AUTOSAR XML (schema 00046)
package /ComponentTypes
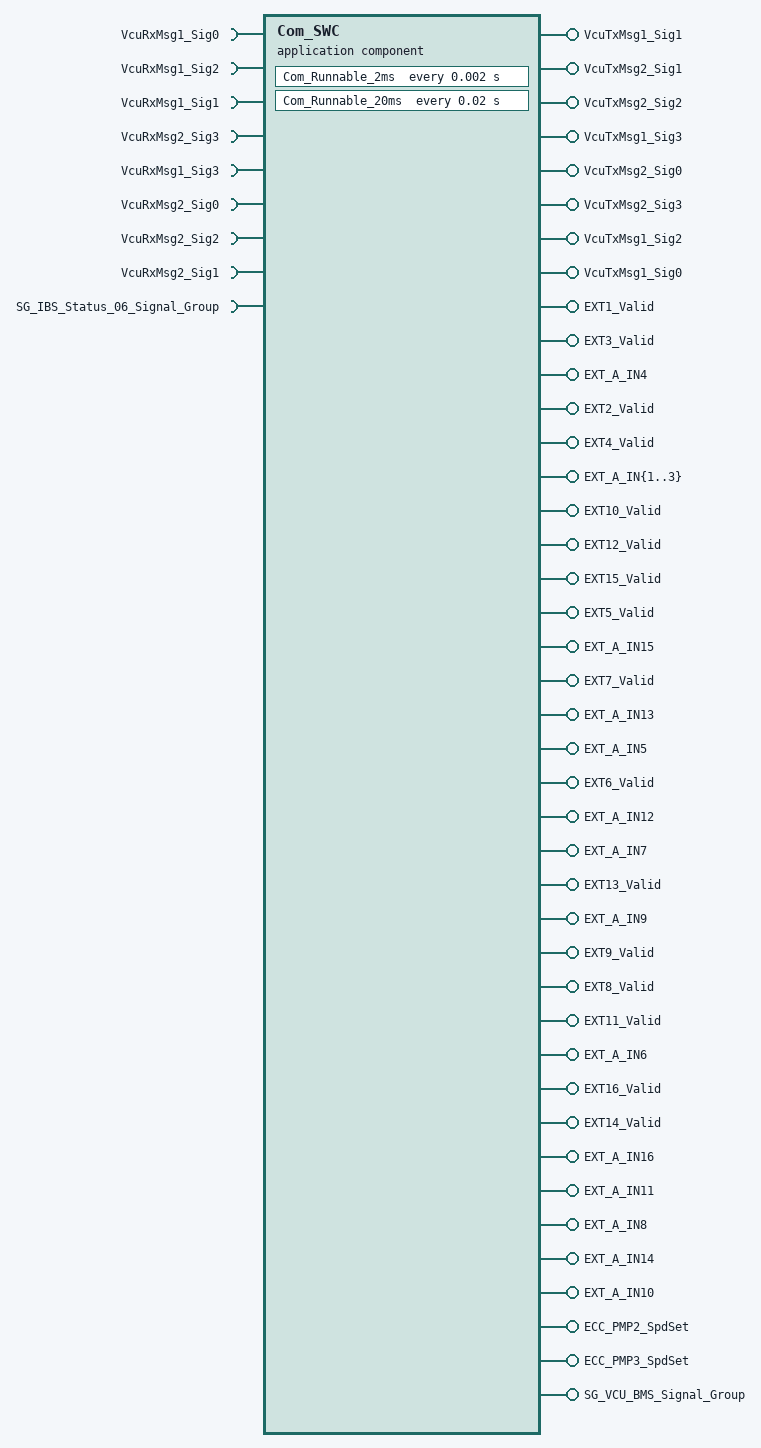
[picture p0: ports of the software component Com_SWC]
  application sw component type Com_SWC
    8 x require port:
      VcuRxMsg1_Sig0: nonqueued-receiver-com-spec{data-element=VcuRxMsg1_Sig0, alive-timeout=2, init-value=0}, required-interface=VcuRxMsg1_Sig0
      VcuRxMsg1_Sig2: nonqueued-receiver-com-spec{data-element=VcuRxMsg1_Sig2, alive-timeout=2, init-value=0}, required-interface=VcuRxMsg1_Sig2
      VcuRxMsg1_Sig1: nonqueued-receiver-com-spec{data-element=VcuRxMsg1_Sig1, alive-timeout=2, init-value=0}, required-interface=VcuRxMsg1_Sig1
      VcuRxMsg2_Sig3: nonqueued-receiver-com-spec{data-element=VcuRxMsg2_Sig3, alive-timeout=2, init-value=0}, required-interface=VcuRxMsg2_Sig3
      VcuRxMsg1_Sig3: nonqueued-receiver-com-spec{data-element=VcuRxMsg1_Sig3, alive-timeout=2, init-value=0}, required-interface=VcuRxMsg1_Sig3
      VcuRxMsg2_Sig0: nonqueued-receiver-com-spec{data-element=VcuRxMsg2_Sig0, alive-timeout=2, init-value=0}, required-interface=VcuRxMsg2_Sig0
      VcuRxMsg2_Sig2: nonqueued-receiver-com-spec{data-element=VcuRxMsg2_Sig2, alive-timeout=2, init-value=0}, required-interface=VcuRxMsg2_Sig2
      VcuRxMsg2_Sig1: nonqueued-receiver-com-spec{data-element=VcuRxMsg2_Sig1, alive-timeout=2, init-value=0}, required-interface=VcuRxMsg2_Sig1
    42 x provide port:
      VcuTxMsg1_Sig1: nonqueued-sender-com-spec{data-element=VcuTxMsg1_Sig1, init-value=0}, provided-interface=VcuTxMsg1_Sig1
      VcuTxMsg2_Sig1: nonqueued-sender-com-spec{data-element=VcuTxMsg2_Sig1, init-value=0}, provided-interface=VcuTxMsg2_Sig1
      VcuTxMsg2_Sig2: nonqueued-sender-com-spec{data-element=VcuTxMsg2_Sig2, init-value=0}, provided-interface=VcuTxMsg2_Sig2
      VcuTxMsg1_Sig3: nonqueued-sender-com-spec{data-element=VcuTxMsg1_Sig3, init-value=0}, provided-interface=VcuTxMsg1_Sig3
      VcuTxMsg2_Sig0: nonqueued-sender-com-spec{data-element=VcuTxMsg2_Sig0, init-value=0}, provided-interface=VcuTxMsg2_Sig0
      VcuTxMsg2_Sig3: nonqueued-sender-com-spec{data-element=VcuTxMsg2_Sig3, init-value=0}, provided-interface=VcuTxMsg2_Sig3
      VcuTxMsg1_Sig2: nonqueued-sender-com-spec{data-element=VcuTxMsg1_Sig2, init-value=0}, provided-interface=VcuTxMsg1_Sig2
      VcuTxMsg1_Sig0: nonqueued-sender-com-spec{data-element=VcuTxMsg1_Sig0, init-value=0}, provided-interface=VcuTxMsg1_Sig0
      EXT1_Valid: nonqueued-sender-com-spec{data-element=EXT1_Valid, init-value=0}, provided-interface=EXT1_Valid
      EXT3_Valid: nonqueued-sender-com-spec{data-element=EXT3_Valid, init-value=0}, provided-interface=EXT3_Valid
      EXT_A_IN4: nonqueued-sender-com-spec{data-element=EXT_A_IN4, init-value=0}, provided-interface=EXT_A_IN4
      EXT2_Valid: nonqueued-sender-com-spec{data-element=EXT2_Valid, init-value=0}, provided-interface=EXT2_Valid
      EXT4_Valid: nonqueued-sender-com-spec{data-element=EXT4_Valid, init-value=0}, provided-interface=EXT4_Valid
      EXT_A_IN{1..3}: nonqueued-sender-com-spec{data-element=EXT_A_IN{1..3}, init-value=0}, provided-interface=EXT_A_IN{1..3}
      EXT10_Valid: nonqueued-sender-com-spec{data-element=EXT10_Valid, init-value=0}, provided-interface=EXT10_Valid
      EXT12_Valid: nonqueued-sender-com-spec{data-element=EXT12_Valid, init-value=0}, provided-interface=EXT12_Valid
      EXT15_Valid: nonqueued-sender-com-spec{data-element=EXT15_Valid, init-value=0}, provided-interface=EXT15_Valid
      EXT5_Valid: nonqueued-sender-com-spec{data-element=EXT5_Valid, init-value=0}, provided-interface=EXT5_Valid
      EXT_A_IN15: nonqueued-sender-com-spec{data-element=EXT_A_IN15, init-value=0}, provided-interface=EXT_A_IN15
      EXT7_Valid: nonqueued-sender-com-spec{data-element=EXT7_Valid, init-value=0}, provided-interface=EXT7_Valid
      EXT_A_IN13: nonqueued-sender-com-spec{data-element=EXT_A_IN13, init-value=0}, provided-interface=EXT_A_IN13
      EXT_A_IN5: nonqueued-sender-com-spec{data-element=EXT_A_IN5, init-value=0}, provided-interface=EXT_A_IN5
      EXT6_Valid: nonqueued-sender-com-spec{data-element=EXT6_Valid, init-value=0}, provided-interface=EXT6_Valid
      EXT_A_IN12: nonqueued-sender-com-spec{data-element=EXT_A_IN12, init-value=0}, provided-interface=EXT_A_IN12
      EXT_A_IN7: nonqueued-sender-com-spec{data-element=EXT_A_IN7, init-value=0}, provided-interface=EXT_A_IN7
      EXT13_Valid: nonqueued-sender-com-spec{data-element=EXT13_Valid, init-value=0}, provided-interface=EXT13_Valid
      EXT_A_IN9: nonqueued-sender-com-spec{data-element=EXT_A_IN9, init-value=0}, provided-interface=EXT_A_IN9
      EXT9_Valid: nonqueued-sender-com-spec{data-element=EXT9_Valid, init-value=0}, provided-interface=EXT9_Valid
      EXT8_Valid: nonqueued-sender-com-spec{data-element=EXT8_Valid, init-value=0}, provided-interface=EXT8_Valid
      EXT11_Valid: nonqueued-sender-com-spec{data-element=EXT11_Valid, init-value=0}, provided-interface=EXT11_Valid
      EXT_A_IN6: nonqueued-sender-com-spec{data-element=EXT_A_IN6, init-value=0}, provided-interface=EXT_A_IN6
      EXT16_Valid: nonqueued-sender-com-spec{data-element=EXT16_Valid, init-value=0}, provided-interface=EXT16_Valid
      EXT14_Valid: nonqueued-sender-com-spec{data-element=EXT14_Valid, init-value=0}, provided-interface=EXT14_Valid
      EXT_A_IN16: nonqueued-sender-com-spec{data-element=EXT_A_IN16, init-value=0}, provided-interface=EXT_A_IN16
      EXT_A_IN11: nonqueued-sender-com-spec{data-element=EXT_A_IN11, init-value=0}, provided-interface=EXT_A_IN11
      EXT_A_IN8: nonqueued-sender-com-spec{data-element=EXT_A_IN8, init-value=0}, provided-interface=EXT_A_IN8
      EXT_A_IN14: nonqueued-sender-com-spec{data-element=EXT_A_IN14, init-value=0}, provided-interface=EXT_A_IN14
      EXT_A_IN10: nonqueued-sender-com-spec{data-element=EXT_A_IN10, init-value=0}, provided-interface=EXT_A_IN10
      ECC_PMP2_SpdSet: nonqueued-sender-com-spec{data-element=ECC_PMP2_SpdSet, init-value=0}, provided-interface=ECC_PMP2_SpdSet
      ECC_PMP3_SpdSet: nonqueued-sender-com-spec{data-element=ECC_PMP3_SpdSet, init-value=0}, provided-interface=ECC_PMP3_SpdSet
    require port SG_IBS_Status_06_Signal_Group: nonqueued-receiver-com-spec{data-element=SG_IBS_Status_06_Signal_Group, uses-end-to-end-protection=true, enable-update=true, filter=data-filter-type=ALWAYS, init-value=fields=[Checksum_0BC:0, IBS_AVHSts:0, IBS_BrakeFluidWarning:0, IBS_EPBFailureStatus:0, IBS_ESClampdisplay:0, IBS_ESCOffSts:0, IBS_FactoryMode:0, IBS_HBAActive:0, IBS_HDCSts:0, IBS_MaintenaceMode:0, IBS_RollerbenchMode:0, IBS_RWUActive:0, IBS_RWUAvailable:0, IBS_TireMonSysSts:0, IBS_TireWarnFrntLe:0, IBS_TireWarnFrntRi:0, IBS_TireWarnReLe:0, IBS_TireWarnReRi:0, IBS_TPMS_ResetSts:0, MessageCounter_0BC:0]}, required-interface=SG_IBS_Status_06_Signal_Group
    provide port SG_VCU_BMS_Signal_Group: nonqueued-sender-com-spec{data-element=SG_VCU_BMS_Signal_Group, uses-end-to-end-protection=true, init-value=fields=[Checksum_0D1:0, MessageCounter_0D1:0, VCU_ActDriveMode:0, VCU_ActiveEnergyProfile:0, VCU_ActiveRgnBrkProfile:0, VCU_BMS_Control_of_NegRelay:0, VCU_BMSTargetThermLevel:0, VCU_Chargestatus:0, VCU_DrvModSwitchWarn:0, VCU_HVStatus:0, VCU_IsomeasurmentSwitch:0, VCU_LimitLevel:0, VCU_RegenBrakeLightRequest:0, VCU_RegenBrakeLightReqVld:0, VCU_RequestedModeBMS:0]}, provided-interface=SG_VCU_BMS_Signal_Group
    behavior Com_SWC_InternalBehavior
      data received event DRT_Rte_Msg200h_Rx_Notification_VcuRxMsg1_Sig0_VcuRxMsg1_Sig0: start-on-event=Rte_Msg200h_Rx_Notification, data=VcuRxMsg1_Sig0.VcuRxMsg1_Sig0
      data received event DRT_Rte_Msg201h_Rx_Notification_VcuRxMsg2_Sig0_VcuRxMsg2_Sig0: start-on-event=Rte_Msg201h_Rx_Notification, data=VcuRxMsg2_Sig0.VcuRxMsg2_Sig0
      timing event TMT_Com_Runnable_2ms: start-on-event=Com_Runnable_2ms, period=0.002
      timing event TMT_Com_Runnable_20ms: start-on-event=Com_Runnable_20ms, period=0.02
      init event Com_SWC_InitEvent: start-on-event=Com_SWC_Init
      5 x runnable:
        Rte_Msg200h_Rx_Notification
        Rte_Msg201h_Rx_Notification
        Com_Runnable_2ms
          data-receive-point-by-arguments:
            9 x access:
              REC_VcuRxMsg1_Sig{0..3}_VcuRxMsg1_Sig{0..3}: accessed-variable=VcuRxMsg1_Sig{0..3}.VcuRxMsg1_Sig{0..3}
              REC_VcuRxMsg2_Sig{0..3}_VcuRxMsg2_Sig{0..3}: accessed-variable=VcuRxMsg2_Sig{0..3}.VcuRxMsg2_Sig{0..3}
              REC_SG_IBS_Status_06_Signal_Group_SG_IBS_Status_06_Signal_Group: accessed-variable=SG_IBS_Status_06_Signal_Group.SG_IBS_Status_06_Signal_Group
          data-send-points:
            43 x access:
              SEND_VcuTxMsg1_Sig{0..3}_VcuTxMsg1_Sig{0..3}: accessed-variable=VcuTxMsg1_Sig{0..3}.VcuTxMsg1_Sig{0..3}
              SEND_VcuTxMsg2_Sig{0..3}_VcuTxMsg2_Sig{0..3}: accessed-variable=VcuTxMsg2_Sig{0..3}.VcuTxMsg2_Sig{0..3}
              SEND_EXT{1..4}_Valid_EXT{1..4}_Valid: accessed-variable=EXT{1..4}_Valid.EXT{1..4}_Valid
              SEND_EXT_A_IN{1..4}_EXT_A_IN{1..4}: accessed-variable=EXT_A_IN{1..4}.EXT_A_IN{1..4}
              SEND_EXT{10..16}_Valid_EXT{10..16}_Valid: accessed-variable=EXT{10..16}_Valid.EXT{10..16}_Valid
              SEND_EXT{5..9}_Valid_EXT{5..9}_Valid: accessed-variable=EXT{5..9}_Valid.EXT{5..9}_Valid
              SEND_EXT_A_IN{10..16}_EXT_A_IN{10..16}: accessed-variable=EXT_A_IN{10..16}.EXT_A_IN{10..16}
              SEND_EXT_A_IN{5..9}_EXT_A_IN{5..9}: accessed-variable=EXT_A_IN{5..9}.EXT_A_IN{5..9}
              SEND_ECC_PMP2_SpdSet_ECC_PMP2_SpdSet: accessed-variable=ECC_PMP2_SpdSet.ECC_PMP2_SpdSet
              SEND_ECC_PMP3_SpdSet_ECC_PMP3_SpdSet: accessed-variable=ECC_PMP3_SpdSet.ECC_PMP3_SpdSet
              SEND_SG_VCU_BMS_Signal_Group_SG_VCU_BMS_Signal_Group: accessed-variable=SG_VCU_BMS_Signal_Group.SG_VCU_BMS_Signal_Group
        Com_Runnable_20ms
        Com_SWC_Init
  swc implementation Com_SWC_Implementation: behavior=Com_SWC_InternalBehavior
